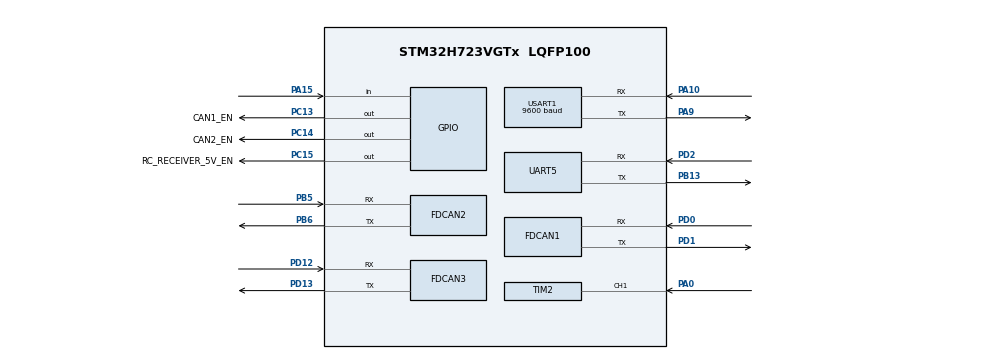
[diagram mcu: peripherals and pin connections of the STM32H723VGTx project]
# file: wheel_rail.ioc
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CORTEX_M7.default_mode_Activation=1
Dma.Request0=UART5_RX
Dma.UART5_RX.0.Direction=DMA_PERIPH_TO_MEMORY
Dma.UART5_RX.0.EventEnable=DISABLE
Dma.UART5_RX.0.FIFOMode=DMA_FIFOMODE_DISABLE
Dma.UART5_RX.0.Instance=DMA1_Stream1
Dma.UART5_RX.0.MemDataAlignment=DMA_MDATAALIGN_BYTE
Dma.UART5_RX.0.MemInc=DMA_MINC_ENABLE
Dma.UART5_RX.0.Mode=DMA_CIRCULAR
Dma.UART5_RX.0.PeriphDataAlignment=DMA_PDATAALIGN_BYTE
Dma.UART5_RX.0.PeriphInc=DMA_PINC_DISABLE
Dma.UART5_RX.0.Polarity=HAL_DMAMUX_REQ_GEN_RISING
Dma.UART5_RX.0.Priority=DMA_PRIORITY_LOW
Dma.UART5_RX.0.RequestNumber=1
Dma.UART5_RX.0.SignalID=NONE
Dma.UART5_RX.0.SyncEnable=DISABLE
Dma.UART5_RX.0.SyncPolarity=HAL_DMAMUX_SYNC_NO_EVENT
Dma.UART5_RX.0.SyncRequestNumber=1
Dma.UART5_RX.0.SyncSignalID=NONE
FDCAN1.AutoRetransmission=ENABLE
FDCAN1.CalculateBaudRateNominal=500000
FDCAN1.CalculateTimeBitNominal=2000
FDCAN1.CalculateTimeQuantumNominal=100.0
FDCAN1.DataSyncJumpWidth=4
FDCAN1.DataTimeSeg1=2
FDCAN1.FrameFormat=FDCAN_FRAME_CLASSIC
FDCAN1.MessageRAMOffset=0
FDCAN1.NominalPrescaler=10
FDCAN1.NominalSyncJumpWidth=1
FDCAN1.NominalTimeSeg1=15
FDCAN1.NominalTimeSeg2=4
FDCAN1.RxFifo0ElmtsNbr=3
FDCAN1.RxFifo0ElmtSize=FDCAN_DATA_BYTES_8
FDCAN1.TxElmtSize=FDCAN_DATA_BYTES_8
FDCAN1.TxFifoQueueElmtsNbr=32
FDCAN2.AutoRetransmission=ENABLE
FDCAN2.CalculateBaudRateNominal=1000000
FDCAN2.CalculateTimeBitNominal=1000
FDCAN2.CalculateTimeQuantumNominal=50.0
FDCAN2.DataSyncJumpWidth=4
FDCAN2.FrameFormat=FDCAN_FRAME_CLASSIC
FDCAN2.MessageRAMOffset=1024
FDCAN2.NominalPrescaler=5
FDCAN2.NominalTimeSeg1=15
FDCAN2.NominalTimeSeg2=4
FDCAN2.RxFifo0ElmtsNbr=32
FDCAN2.RxFifo0ElmtSize=FDCAN_DATA_BYTES_8
FDCAN2.TxElmtSize=FDCAN_DATA_BYTES_8
FDCAN2.TxFifoQueueElmtsNbr=32
FDCAN3.AutoRetransmission=ENABLE
FDCAN3.CalculateBaudRateData=4000000
FDCAN3.CalculateBaudRateNominal=1000000
FDCAN3.DataPrescaler=1
FDCAN3.DataSyncJumpWidth=5
FDCAN3.DataTimeSeg1=19
FDCAN3.DataTimeSeg2=5
FDCAN3.FrameFormat=FDCAN_FRAME_FD_BRS
FDCAN3.MessageRAMOffset=1536
FDCAN3.NominalPrescaler=5
FDCAN3.NominalSyncJumpWidth=4
FDCAN3.NominalTimeSeg1=15
FDCAN3.NominalTimeSeg2=4
FDCAN3.RxFifo0ElmtSize=FDCAN_DATA_BYTES_64
FDCAN3.RxFifo0ElmtsNbr=32
FDCAN3.StdFiltersNbr=4
FDCAN3.TxElmtSize=FDCAN_DATA_BYTES_64
FDCAN3.TxFifoQueueElmtsNbr=16
Mcu.Family=STM32H7
Mcu.Name=STM32H723VGTx
Mcu.Package=LQFP100
NVIC.DMA1_Stream1_IRQn=true\:0\:0\:false\:false\:true\:false\:true\:true
NVIC.FDCAN1_IT0_IRQn=true\:0\:0\:false\:false\:true\:true\:true\:true
NVIC.FDCAN1_IT1_IRQn=true\:0\:0\:false\:false\:true\:true\:true\:true
NVIC.FDCAN2_IT0_IRQn=true\:0\:0\:true\:false\:true\:true\:true\:true
NVIC.FDCAN3_IT0_IRQn=true\:0\:0\:true\:false\:true\:true\:true\:true
NVIC.PriorityGroup=NVIC_PRIORITYGROUP_4
NVIC.TIM15_IRQn=true\:0\:0\:false\:false\:true\:true\:true\:true
NVIC.TIM6_DAC_IRQn=true\:0\:0\:true\:false\:true\:true\:true\:true
NVIC.UART5_IRQn=true\:0\:0\:false\:false\:true\:true\:true\:true
NVIC.USART1_IRQn=true\:0\:0\:false\:false\:true\:true\:true\:true
PA0.Signal=S_TIM2_CH1_ETR
PA10.Mode=Asynchronous
PA10.Signal=USART1_RX
PA13(JTMS/SWDIO).Mode=Serial_Wire
PA13(JTMS/SWDIO).Signal=DEBUG_JTMS-SWDIO
PA14(JTCK/SWCLK).Mode=Serial_Wire
PA14(JTCK/SWCLK).Signal=DEBUG_JTCK-SWCLK
PA15(JTDI).GPIO_PuPd=GPIO_PULLUP
PA15(JTDI).Signal=GPIO_Input
PA9.Mode=Asynchronous
PA9.Signal=USART1_TX
PB13.Mode=Asynchronous
PB13.Signal=UART5_TX
PB5.Mode=FDCAN_Activate
PB5.Signal=FDCAN2_RX
PB6.Mode=FDCAN_Activate
PB6.Signal=FDCAN2_TX
PC13.GPIO_Label=CAN1_EN
PC13.Signal=GPIO_Output
PC14-OSC32_IN.GPIO_Label=CAN2_EN
PC14-OSC32_IN.Signal=GPIO_Output
PC15-OSC32_OUT.GPIO_Label=RC_RECEIVER_5V_EN
PC15-OSC32_OUT.Signal=GPIO_Output
PD0.Mode=FDCAN_Activate
PD0.Signal=FDCAN1_RX
PD1.Mode=FDCAN_Activate
PD1.Signal=FDCAN1_TX
PD12.Mode=FDCAN_Activate
PD12.Signal=FDCAN3_RX
PD13.Mode=FDCAN_Activate
PD13.Signal=FDCAN3_TX
PD2.Mode=Asynchronous
PD2.Signal=UART5_RX
PH0-OSC_IN.Mode=HSE-External-Oscillator
PH0-OSC_IN.Signal=RCC_OSC_IN
PH1-OSC_OUT.Mode=HSE-External-Oscillator
PH1-OSC_OUT.Signal=RCC_OSC_OUT
ProjectManager.HeapSize=0x200
ProjectManager.StackSize=0x400
ProjectManager.TargetToolchain=STM32CubeIDE
RCC.ADCFreq_Value=129000000
RCC.APB1Freq_Value=100000000
RCC.APB2Freq_Value=50000000
RCC.APB3Freq_Value=100000000
RCC.APB4Freq_Value=100000000
RCC.CortexFreq_Value=200000000
RCC.D1PPRE=RCC_APB3_DIV2
RCC.D2PPRE1=RCC_APB1_DIV2
RCC.D2PPRE2=RCC_APB2_DIV4
RCC.D3PPRE=RCC_APB4_DIV2
RCC.DIVM1=4
RCC.DIVN1=12
RCC.DIVP1=1
RCC.FDCANCLockSelection=RCC_FDCANCLKSOURCE_PLL
RCC.HCLKFreq_Value=200000000
RCC.HSI48State=RCC_HSI48_ON
RCC.PLL2FRACN=0
RCC.PLL3FRACN=0
RCC.PLLFRACN=4096
RCC.RNGCLockSelection=RCC_RNGCLKSOURCE_HSI48
RCC.SYSCLKFreq_VALUE=200000000
RCC.SYSCLKSource=RCC_SYSCLKSOURCE_PLLCLK
RCC.USBFreq_Value=100000000
SH.S_TIM2_CH1_ETR.0=TIM2_CH1,Input_Capture1_from_TI1
TIM15.AutoReloadPreload=TIM_AUTORELOAD_PRELOAD_ENABLE
TIM15.Period=999
TIM15.Prescaler=4999
TIM2.AutoReloadPreload=TIM_AUTORELOAD_PRELOAD_ENABLE
TIM2.Channel-Input_Capture1_from_TI1=TIM_CHANNEL_1
TIM2.Period=99
TIM2.Prescaler=999
TIM5.AutoReloadPreload=TIM_AUTORELOAD_PRELOAD_DISABLE
TIM5.Period=4294967295
TIM5.Prescaler=199
TIM6.AutoReloadPreload=TIM_AUTORELOAD_PRELOAD_ENABLE
TIM6.Period=99
TIM6.Prescaler=19999
UART5.RxPinLevelInvertParam=UART_ADVFEATURE_RXINV_ENABLE
USART1.BaudRate=9600
USART1.Parity=PARITY_NONE
USART1.RxPinLevelInvertParam=ADVFEATURE_RXINV_ENABLE
USART1.StopBits=STOPBITS_1
USART1.VirtualMode-Asynchronous=VM_ASYNC
USART1.WordLength=WORDLENGTH_8B
VP_MEMORYMAP_VS_MEMORYMAP.Mode=CurAppReg
VP_TIM15_VS_ClockSourceINT.Mode=Internal
VP_TIM2_VS_ClockSourceINT.Mode=Internal
VP_TIM5_VS_ClockSourceINT.Mode=Internal
VP_TIM6_VS_ClockSourceINT.Mode=Enable_Timer
board=custom

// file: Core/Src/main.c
/* USER CODE BEGIN Header */
/**
  ******************************************************************************
  * @file           : main.c
  * @brief          : Main program body
  ******************************************************************************
  * @attention
  *
  * Copyright (c) 2026 STMicroelectronics.
  * All rights reserved.
  *
  * This software is licensed under terms that can be found in the LICENSE file
  * in the root directory of this software component.
  * If no LICENSE file comes with this software, it is provided AS-IS.
  *
  ******************************************************************************
  */
/* USER CODE END Header */
#include "main.h"
#include "dma.h"
#include "fdcan.h"
#include "tim.h"
#include "rng.h"
#include "usart.h"
#include "gpio.h"

/* USER CODE BEGIN Includes */
#include "entry.h"
#include "stm32_board_port.h"
#include "stm32_host_can_port.h"
#include "stm32_time_port.h"
/* USER CODE END Includes */

void SystemClock_Config(void);
static void MPU_Config(void);

int main(void)
{

  /* MPU Configuration--------------------------------------------------------*/
  MPU_Config();

  /* MCU Configuration--------------------------------------------------------*/

  /* Reset of all peripherals, Initializes the Flash interface and the Systick. */
  HAL_Init();

  /* Configure the system clock */
  SystemClock_Config();

  /* Initialize all configured peripherals */
  MX_GPIO_Init();
  stm32_board_receiver_power_enable();
  MX_DMA_Init();
  MX_FDCAN1_Init();
  MX_USART1_UART_Init();
  MX_TIM2_Init();
  MX_TIM6_Init();
  MX_UART5_Init();
  MX_FDCAN2_Init();
  MX_TIM15_Init();
  MX_TIM5_Init();
  MX_RNG_Init();
  MX_FDCAN3_Init();
  /* USER CODE BEGIN 2 */
  if (!stm32_time_init()) {
    Error_Handler();
  }
  uint32_t boot_id;
  if (!stm32_board_boot_id(&boot_id)) {
    Error_Handler();
  }
  if (!stm32_host_can_init()) {
    Error_Handler();
  }
  entry_init();
  /* USER CODE END 2 */

  /* Infinite loop */
  while (1)
  {

    /* USER CODE BEGIN 3 */
    entry_loop();
  }
  /* USER CODE END 3 */
}

void SystemClock_Config(void)
{
  RCC_OscInitTypeDef RCC_OscInitStruct = {0};
  RCC_ClkInitTypeDef RCC_ClkInitStruct = {0};
  RCC_PeriphCLKInitTypeDef PeriphClkInitStruct = {0};

  /** Supply configuration update enable
  */
  HAL_PWREx_ConfigSupply(PWR_LDO_SUPPLY);

  /** Configure the main internal regulator output voltage
  */
  __HAL_PWR_VOLTAGESCALING_CONFIG(PWR_REGULATOR_VOLTAGE_SCALE1);

  while(!__HAL_PWR_GET_FLAG(PWR_FLAG_VOSRDY)) {}

  /** Initializes the RCC Oscillators according to the specified parameters
  * in the RCC_OscInitTypeDef structure.
  */
  RCC_OscInitStruct.OscillatorType = RCC_OSCILLATORTYPE_HSI|RCC_OSCILLATORTYPE_HSI48;
  RCC_OscInitStruct.HSIState = RCC_HSI_DIV1;
  RCC_OscInitStruct.HSI48State = RCC_HSI48_ON;
  RCC_OscInitStruct.HSICalibrationValue = 64;
  RCC_OscInitStruct.PLL.PLLState = RCC_PLL_ON;
  RCC_OscInitStruct.PLL.PLLSource = RCC_PLLSOURCE_HSI;
  RCC_OscInitStruct.PLL.PLLM = 4;
  RCC_OscInitStruct.PLL.PLLN = 12;
  RCC_OscInitStruct.PLL.PLLP = 1;
  RCC_OscInitStruct.PLL.PLLQ = 2;
  RCC_OscInitStruct.PLL.PLLR = 2;
  RCC_OscInitStruct.PLL.PLLRGE = RCC_PLL1VCIRANGE_3;
  RCC_OscInitStruct.PLL.PLLVCOSEL = RCC_PLL1VCOWIDE;
  RCC_OscInitStruct.PLL.PLLFRACN = 4096;
  if (HAL_RCC_OscConfig(&RCC_OscInitStruct) != HAL_OK)
  {
    Error_Handler();
  }

  PeriphClkInitStruct.PeriphClockSelection = RCC_PERIPHCLK_FDCAN|RCC_PERIPHCLK_RNG;
  PeriphClkInitStruct.FdcanClockSelection = RCC_FDCANCLKSOURCE_PLL;
  PeriphClkInitStruct.RngClockSelection = RCC_RNGCLKSOURCE_HSI48;
  if (HAL_RCCEx_PeriphCLKConfig(&PeriphClkInitStruct) != HAL_OK)
  {
    Error_Handler();
  }

  /** Initializes the CPU, AHB and APB buses clocks
  */
  RCC_ClkInitStruct.ClockType = RCC_CLOCKTYPE_HCLK|RCC_CLOCKTYPE_SYSCLK
                              |RCC_CLOCKTYPE_PCLK1|RCC_CLOCKTYPE_PCLK2
                              |RCC_CLOCKTYPE_D3PCLK1|RCC_CLOCKTYPE_D1PCLK1;
  RCC_ClkInitStruct.SYSCLKSource = RCC_SYSCLKSOURCE_PLLCLK;
  RCC_ClkInitStruct.SYSCLKDivider = RCC_SYSCLK_DIV1;
  RCC_ClkInitStruct.AHBCLKDivider = RCC_HCLK_DIV1;
  RCC_ClkInitStruct.APB3CLKDivider = RCC_APB3_DIV2;
  RCC_ClkInitStruct.APB1CLKDivider = RCC_APB1_DIV2;
  RCC_ClkInitStruct.APB2CLKDivider = RCC_APB2_DIV4;
  RCC_ClkInitStruct.APB4CLKDivider = RCC_APB4_DIV2;

  if (HAL_RCC_ClockConfig(&RCC_ClkInitStruct, FLASH_LATENCY_2) != HAL_OK)
  {
    Error_Handler();
  }
}

 /* MPU Configuration */

void MPU_Config(void)
{
  MPU_Region_InitTypeDef MPU_InitStruct = {0};

  /* Disables the MPU */
  HAL_MPU_Disable();

  /** Initializes and configures the Region and the memory to be protected
  */
  MPU_InitStruct.Enable = MPU_REGION_ENABLE;
  MPU_InitStruct.Number = MPU_REGION_NUMBER0;
  MPU_InitStruct.BaseAddress = 0x0;
  MPU_InitStruct.Size = MPU_REGION_SIZE_4GB;
  MPU_InitStruct.SubRegionDisable = 0x87;
  MPU_InitStruct.TypeExtField = MPU_TEX_LEVEL0;
  MPU_InitStruct.AccessPermission = MPU_REGION_NO_ACCESS;
  MPU_InitStruct.DisableExec = MPU_INSTRUCTION_ACCESS_DISABLE;
  MPU_InitStruct.IsShareable = MPU_ACCESS_SHAREABLE;
  MPU_InitStruct.IsCacheable = MPU_ACCESS_NOT_CACHEABLE;
  MPU_InitStruct.IsBufferable = MPU_ACCESS_NOT_BUFFERABLE;

  HAL_MPU_ConfigRegion(&MPU_InitStruct);
  /* Enables the MPU */
  HAL_MPU_Enable(MPU_PRIVILEGED_DEFAULT);

}

void Error_Handler(void)
{
  __disable_irq();
  while (1)
  {
  }
}
